# ATSAMC21N17A register map
Registers are 32-bit, access not given, no defined reset value unless marked. A register's access mark holds for its fields unless they carry their own. Addresses are absolute; registers are grouped by the start of their names; [hi:lo] are bit positions; {n}, {i} and the like mark numbered series; 'fields as' and 'values as' point back to an identical list.

## OSC32KCTRL
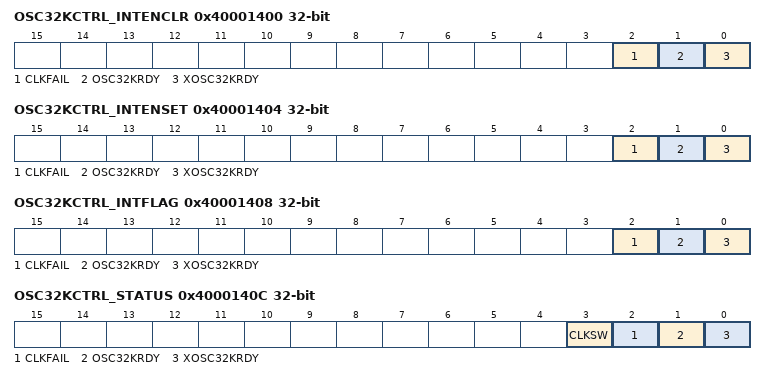
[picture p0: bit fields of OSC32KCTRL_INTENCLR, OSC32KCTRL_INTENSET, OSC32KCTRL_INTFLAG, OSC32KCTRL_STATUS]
0x40001400 OSC32KCTRL_INTENCLR — Interrupt Enable Clear
  [2] CLKFAIL, [1] OSC32KRDY, [0] XOSC32KRDY
0x40001404 OSC32KCTRL_INTENSET — Interrupt Enable Set
  [2] CLKFAIL, [1] OSC32KRDY, [0] XOSC32KRDY
0x40001408 OSC32KCTRL_INTFLAG — Interrupt Flag Status and Clear
  [2] CLKFAIL, [1] OSC32KRDY, [0] XOSC32KRDY
0x4000140C OSC32KCTRL_STATUS — Power and Clocks Status
  [3] CLKSW, [2] CLKFAIL, [1] OSC32KRDY, [0] XOSC32KRDY
0x40001410 OSC32KCTRL_RTCCTRL — Clock selection
  [2:0] RTCSEL
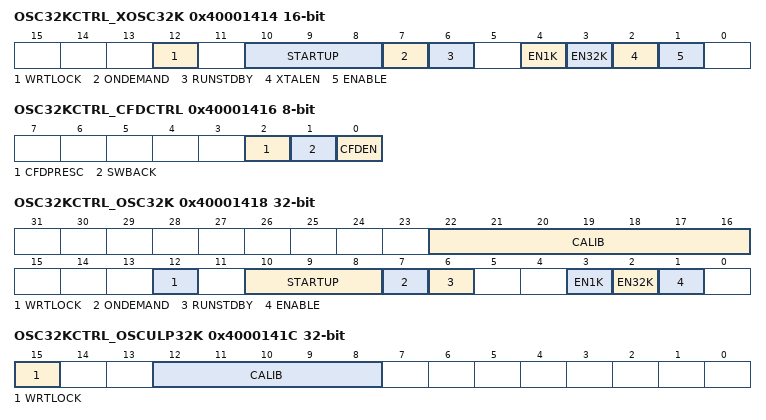
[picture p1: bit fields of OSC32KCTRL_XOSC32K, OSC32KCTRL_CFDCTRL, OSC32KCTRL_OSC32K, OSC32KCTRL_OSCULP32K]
0x40001414 OSC32KCTRL_XOSC32K 16-bit — 32kHz External Crystal Oscillator (XOSC32K) Control
  [12] WRTLOCK, [10:8] STARTUP, [7] ONDEMAND, [6] RUNSTDBY, [4] EN1K, [3] EN32K, [2] XTALEN, [1] ENABLE
0x40001416 OSC32KCTRL_CFDCTRL 8-bit — Clock Failure Detector Control
  [2] CFDPRESC, [1] SWBACK, [0] CFDEN
0x40001417 OSC32KCTRL_EVCTRL 8-bit — Event Control
  [0] CFDEO
0x40001418 OSC32KCTRL_OSC32K — 32kHz Internal Oscillator (OSC32K) Control
  [22:16] CALIB, [12] WRTLOCK, [10:8] STARTUP, [7] ONDEMAND, [6] RUNSTDBY, [3] EN1K, [2] EN32K, [1] ENABLE
0x4000141C OSC32KCTRL_OSCULP32K — 32kHz Ultra Low Power Internal Oscillator (OSCULP32K) Control
  [15] WRTLOCK, [12:8] CALIB

## PAC
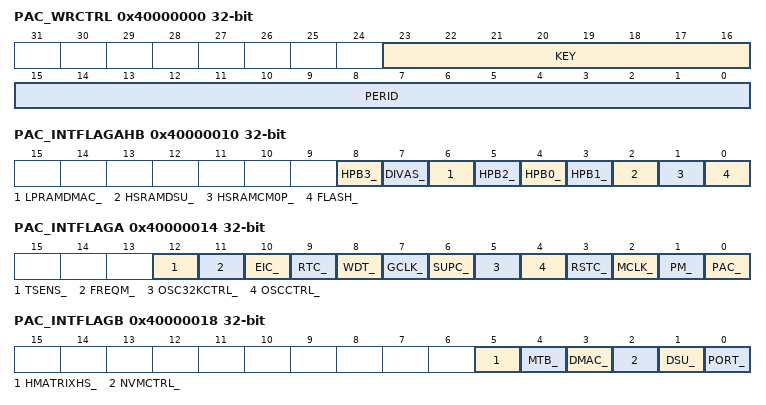
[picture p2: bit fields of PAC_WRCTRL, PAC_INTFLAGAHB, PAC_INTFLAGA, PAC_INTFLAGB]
0x40000000 PAC_WRCTRL — Write control
  [23:16] KEY, [15:0] PERID
0x40000004 PAC_EVCTRL 8-bit — Event control
  [0] ERREO
0x40000008 PAC_INTENCLR 8-bit — Interrupt enable clear
  [0] ERR
0x40000009 PAC_INTENSET 8-bit — Interrupt enable set
  [0] ERR
0x40000010 PAC_INTFLAGAHB — Bridge interrupt flag status
  [8] HPB3_, [7] DIVAS_, [6] LPRAMDMAC_, [5] HPB2_, [4] HPB0_, [3] HPB1_, [2] HSRAMDSU_, [1] HSRAMCM0P_, [0] FLASH_
0x40000014 PAC_INTFLAGA — Peripheral interrupt flag status - Bridge A
  [12] TSENS_, [11] FREQM_, [10] EIC_, [9] RTC_, [8] WDT_, [7] GCLK_, [6] SUPC_, [5] OSC32KCTRL_, [4] OSCCTRL_, [3] RSTC_, [2] MCLK_, [1] PM_, [0] PAC_
0x40000018 PAC_INTFLAGB — Peripheral interrupt flag status - Bridge B
  [5] HMATRIXHS_, [4] MTB_, [3] DMAC_, [2] NVMCTRL_, [1] DSU_, [0] PORT_
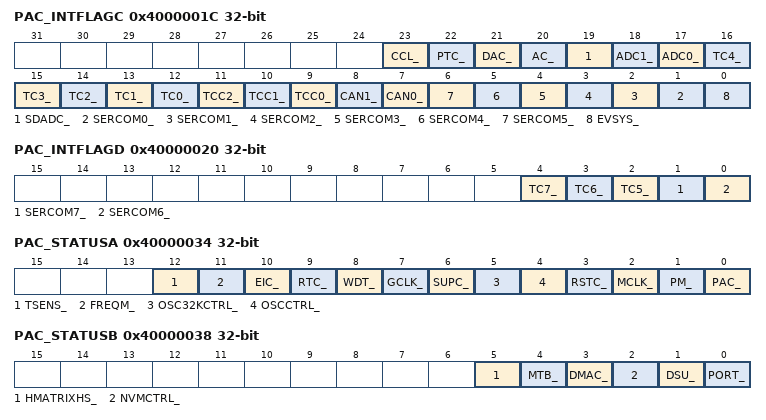
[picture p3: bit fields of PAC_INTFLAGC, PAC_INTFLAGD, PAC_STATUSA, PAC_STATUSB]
0x4000001C PAC_INTFLAGC — Peripheral interrupt flag status - Bridge C
  [23] CCL_, [22] PTC_, [21] DAC_, [20] AC_, [19] SDADC_, [18] ADC1_, [17] ADC0_, [n+12] TC{n}_ (n=0..4), [11] TCC2_, [10] TCC1_, [9] TCC0_, [8] CAN1_, [7] CAN0_, [n+1] SERCOM{n}_ (n=0..5), [0] EVSYS_
0x40000020 PAC_INTFLAGD — Peripheral interrupt flag status - Bridge D
  [4] TC7_, [3] TC6_, [2] TC5_, [1] SERCOM7_, [0] SERCOM6_
0x40000034 PAC_STATUSA — Peripheral write protection status - Bridge A
  fields as PAC_INTFLAGA
0x40000038 PAC_STATUSB — Peripheral write protection status - Bridge B
  fields as PAC_INTFLAGB
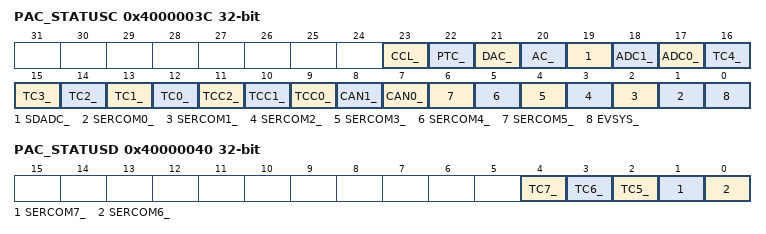
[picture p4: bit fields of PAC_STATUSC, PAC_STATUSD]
0x4000003C PAC_STATUSC — Peripheral write protection status - Bridge C
  fields as PAC_INTFLAGC
0x40000040 PAC_STATUSD — Peripheral write protection status - Bridge D
  [4] TC7_, [3] TC6_, [2] TC5_, [1] SERCOM7_, [0] SERCOM6_

## PM
0x40000401 PM_SLEEPCFG 8-bit — Sleep Configuration
  [2:0] SLEEPMODE
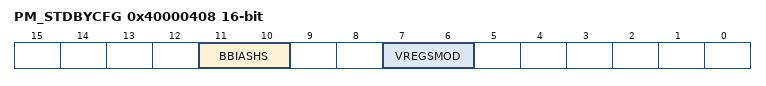
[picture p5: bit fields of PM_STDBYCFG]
0x40000408 PM_STDBYCFG 16-bit — Standby Configuration
  [11:10] BBIASHS, [7:6] VREGSMOD

## PORT
0x41000000 PORT_DIR — Data Direction
0x41000004 PORT_DIRCLR — Data Direction Clear
0x41000008 PORT_DIRSET — Data Direction Set
0x4100000C PORT_DIRTGL — Data Direction Toggle
0x41000010 PORT_OUT — Data Output Value
0x41000014 PORT_OUTCLR — Data Output Value Clear
0x41000018 PORT_OUTSET — Data Output Value Set
0x4100001C PORT_OUTTGL — Data Output Value Toggle
0x41000020 PORT_IN — Data Input Value
0x41000024 PORT_CTRL — Control
  [31:0] SAMPLING
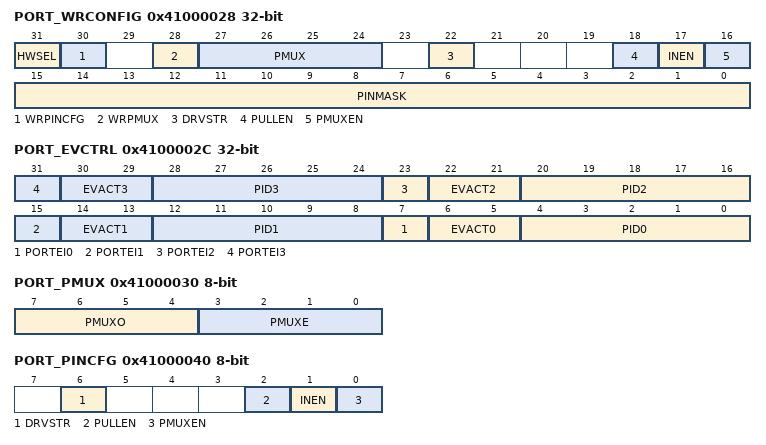
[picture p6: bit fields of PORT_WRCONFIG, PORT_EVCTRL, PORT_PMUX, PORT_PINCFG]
0x41000028 PORT_WRCONFIG — Write Configuration
  [31] HWSEL, [30] WRPINCFG, [28] WRPMUX, [27:24] PMUX, [22] DRVSTR, [18] PULLEN, [17] INEN, [16] PMUXEN, [15:0] PINMASK
0x4100002C PORT_EVCTRL — Event Input Control
  [8n+7] PORTEI{n} (n=0..3), [8n+6:8n+5] EVACT{n} (n=0..3), [8n+4:8n] PID{n} (n=0..3)
0x41000030 PORT_PMUX 8-bit — Peripheral Multiplexing n
  [7:4] PMUXO, [3:0] PMUXE
0x41000040 PORT_PINCFG 8-bit — Pin Configuration n
  [6] DRVSTR, [2] PULLEN, [1] INEN, [0] PMUXEN
0x60000000 PORT_DIR — Data Direction
0x60000004 PORT_DIRCLR — Data Direction Clear
0x60000008 PORT_DIRSET — Data Direction Set
0x6000000C PORT_DIRTGL — Data Direction Toggle
0x60000010 PORT_OUT — Data Output Value
0x60000014 PORT_OUTCLR — Data Output Value Clear
0x60000018 PORT_OUTSET — Data Output Value Set
0x6000001C PORT_OUTTGL — Data Output Value Toggle
0x60000020 PORT_IN — Data Input Value
0x60000024 PORT_CTRL — Control
  [31:0] SAMPLING
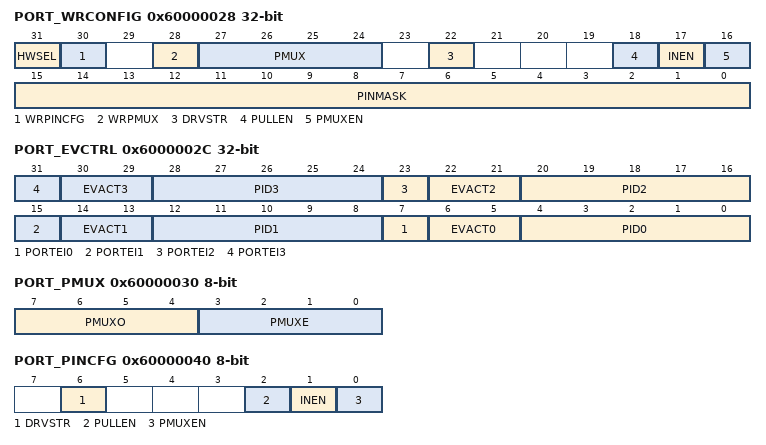
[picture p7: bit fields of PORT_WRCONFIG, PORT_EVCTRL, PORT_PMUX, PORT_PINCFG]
0x60000028 PORT_WRCONFIG — Write Configuration
  fields as PORT_WRCONFIG
0x6000002C PORT_EVCTRL — Event Input Control
  fields as PORT_EVCTRL
0x60000030 PORT_PMUX 8-bit — Peripheral Multiplexing n
  [7:4] PMUXO, [3:0] PMUXE
0x60000040 PORT_PINCFG 8-bit — Pin Configuration n
  [6] DRVSTR, [2] PULLEN, [1] INEN, [0] PMUXEN
